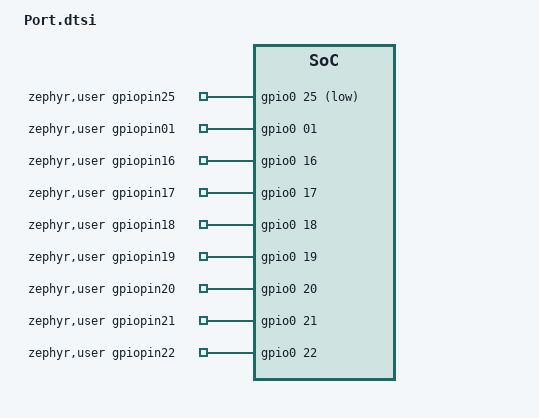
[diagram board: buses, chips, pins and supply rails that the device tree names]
/* This file is auto-generated by E:\labs\zephyr-lab\Car-OS.Zephyr\car-os\tools\gui\port\port_cgen.py
   file. Any hand-modification will be lost! */
#include <zephyr/dt-bindings/gpio/gpio.h>

/ {
	zephyr,user {
		gpiopin25-gpios = <&gpio0 25 GPIO_ACTIVE_LOW>;
		gpiopin01-gpios = <&gpio0 01 GPIO_ACTIVE_HIGH>;
		gpiopin16-gpios = <&gpio0 16 GPIO_ACTIVE_HIGH>;
		gpiopin17-gpios = <&gpio0 17 GPIO_ACTIVE_HIGH>;
		gpiopin18-gpios = <&gpio0 18 GPIO_ACTIVE_HIGH>;
		gpiopin19-gpios = <&gpio0 19 GPIO_ACTIVE_HIGH>;
		gpiopin20-gpios = <&gpio0 20 GPIO_ACTIVE_HIGH>;
		gpiopin21-gpios = <&gpio0 21 GPIO_ACTIVE_HIGH>;
		gpiopin22-gpios = <&gpio0 22 GPIO_ACTIVE_HIGH>;
	};
};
